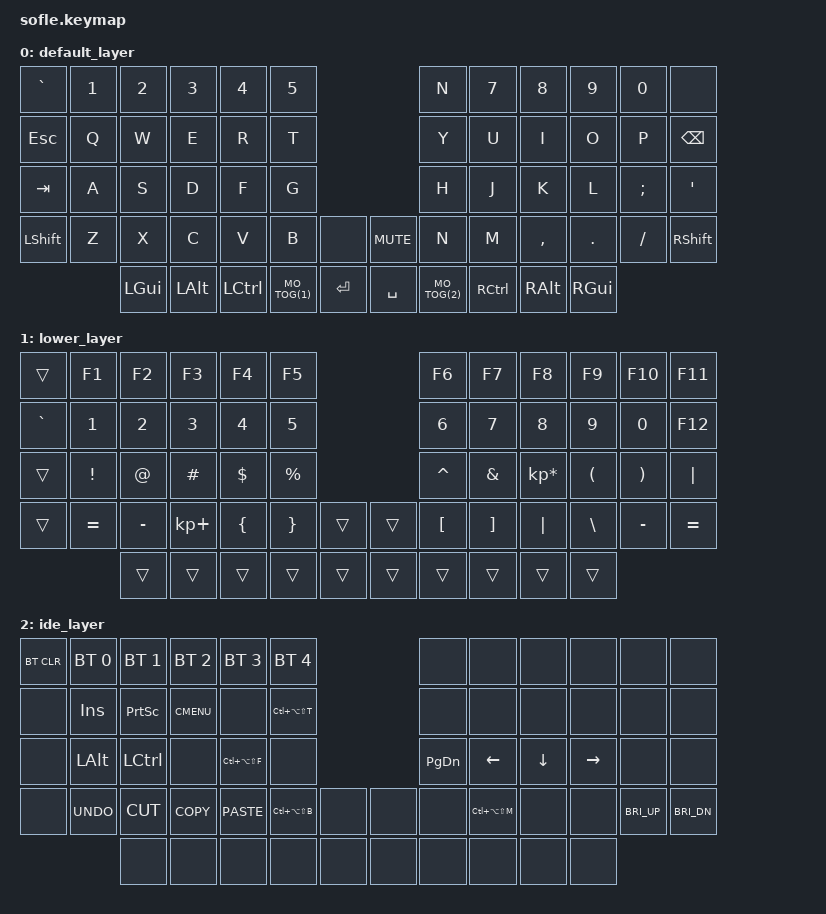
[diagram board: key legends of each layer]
/*
 * Copyright (c) 2020 The ZMK Contributors
 *
 * SPDX-License-Identifier: MIT
 */

#include <behaviors.dtsi>
#include <dt-bindings/zmk/keys.h>
#include <dt-bindings/zmk/bt.h>
#include <dt-bindings/zmk/rgb.h>

#define MO_TOG(layer) &mo_tog layer layer
#define IDE_MENU &kp LC(LA(LS(M)))
#define IDE_TERMFOCUS &kp LC(LA(LS(T)))
#define IDE_FILEFOCUS &kp LC(LA(LS(F)))
#define IDE_SBARFOCUS &kp LC(LA(LS(B)))

/ {
    behaviors {
        mo_tog: behavior_mo_tog {
            compatible = "zmk,behavior-hold-tap";
            #binding-cells = <2>;
            flavor = "hold-preferred";
            tapping-term-ms = <200>;
            bindings = <&mo>, <&tog>;
        };
    };

    keymap {
        compatible = "zmk,keymap";

        default_layer {
// ------------------------------------------------------------------------------------------------------------
// |  `    |  1  |  2  |  3   |  4   |  5   |                   |  6   |  7    |  8    |  9   |   0   |       |
// |  ESC  |  Q  |  W  |  E   |  R   |  T   |                   |  Y   |  U    |  I    |  O   |   P   | BKSPC |
// |  TAB  |  A  |  S  |  D   |  F   |  G   |                   |  H   |  J    |  K    |  L   |   ;   |   '   |
// | SHIFT |  Z  |  X  |  C   |  V   |  B   |        |  |  MUTE |  N   |  M    |  ,    |  .   |   /   | SHIFT |
//               |LGUI | ALT  | CTRL | LOWER|  ENTER |  | SPACE | RAISE| CTRL  | ALT   | GUI  |
            bindings = <
&kp GRAVE &kp N1 &kp N2   &kp N3   &kp N4    &kp N5                             &kp N      &kp N7    &kp N8    &kp N9   &kp N0   &none
&kp ESC   &kp Q  &kp W    &kp E    &kp R     &kp T                              &kp Y      &kp U     &kp I     &kp O    &kp P    &kp BSPC
&kp TAB   &kp A  &kp S    &kp D    &kp F     &kp G                              &kp H      &kp J     &kp K     &kp L    &kp SEMI &kp SQT
&kp LSHFT &kp Z  &kp X    &kp C    &kp V     &kp B      &none       &kp K_MUTE  &kp N      &kp M     &kp COMMA &kp DOT  &kp FSLH &kp RSHFT
                 &kp LGUI &kp LALT &kp LCTRL MO_TOG(1)  &kp RET     &kp SPACE   MO_TOG(2)  &kp RCTRL &kp RALT  &kp RGUI
            >;

            sensor-bindings = <&inc_dec_kp C_BRI_UP C_BRI_DN &inc_dec_kp C_VOL_UP C_VOL_DN>;
        };

        lower_layer {
// TODO: Some binds are waiting for shifted keycode support.
// ------------------------------------------------------------------------------------------------------------
// |       |  F1 |  F2 |  F3  |  F4  |  F5  |                   |  F6  |  F7   |  F8   |  F9  |  F10  |  F11  |
// | `     |  1  |  2  |  3   |  4   |  5   |                   |  6   |   7   |  8    |  9   |   0   |  F12  |
// |       |  !  |  @  |  #   |  $   |  %   |                   |  ^   |   &   |  *    |  (   |   )   |   |   |
// |       |  =  |  -  |  +   |  {   |  }   |        |  |       |  [   |   ]   |  |    |  \   |   -   |   +   |
//               |     |      |      |      |        |  |       |      |       |       |      |
            bindings = <
&trans    &kp F1    &kp F2    &kp F3      &kp F4    &kp F5                    &kp F6    &kp F7   &kp F8          &kp F9    &kp F10   &kp F11
&kp GRAVE &kp N1    &kp N2    &kp N3      &kp N4    &kp N5                    &kp N6    &kp N7   &kp N8          &kp N9    &kp N0    &kp F12
&trans    &kp EXCL  &kp AT    &kp HASH    &kp DLLR  &kp PRCNT                 &kp CARET &kp AMPS &kp KP_MULTIPLY &kp LPAR  &kp RPAR  &kp PIPE
&trans    &kp EQUAL &kp MINUS &kp KP_PLUS &kp LBRC  &kp RBRC  &trans   &trans &kp LBKT  &kp RBKT &kp PIPE        &kp BSLH  &kp MINUS &kp EQUAL
                    &trans    &trans      &trans    &trans    &trans   &trans &trans    &trans   &trans          &trans
            >;

            sensor-bindings = <&inc_dec_kp C_BRI_UP C_BRI_DN &inc_dec_kp C_VOL_UP C_VOL_DN>;
        };

        ide_layer {
// ------------------------------------------------------------------------------------------------------------
// |    BTCLR   |     BT0      |     BT1      |      BT2     |      BT3      |      BT4      |                            |              |              |            |           |             |             |
// |            |     INS      |     PSCR     |     GUI      |               | IDE_TERMFOCUS |                            |     PGUP     |              |      ^     |           |             |             |
// |            |     ALT      |     CTRL     |    FOCFLS    | IDE_FILEFOCUS |     CAPS      |                            |     PGDN     |      <-      |      v     |     ->    |             |             |
// |            |     UNDO     |     CUT      |     COPY     |     PASTE     | IDE_SBARFOCUS |            |  |            |              |   IDE_MENU   |            |           |   BRIGHT    |  DIM        |
//                             |              |              |               |               |            |  |            |              |              |            |           |                       
            bindings = <
    &bt BT_CLR  &bt BT_SEL 0    &bt BT_SEL 1   &bt BT_SEL 2   &bt BT_SEL 3    &bt BT_SEL 4                                 &none           &none          &none       &none       &none          &none
    &none       &kp INS         &kp PSCRN      &kp K_CMENU    &none           IDE_TERMFOCUS                                &none           &none          &none       &none       &none          &none
    &none       &kp LALT        &kp LCTRL      &none          IDE_FILEFOCUS   &none                                        &kp PG_DN       &kp LEFT       &kp DOWN    &kp RIGHT   &none          &none
    &none       &kp K_UNDO      &kp K_CUT      &kp K_COPY     &kp K_PASTE     IDE_SBARFOCUS   &none           &none        &none           IDE_MENU       &none       &none       &kp C_BRI_UP   &kp C_BRI_DN
                                &none          &none          &none           &none           &none           &none        &none           &none          &none       &none                               
            >;

            sensor-bindings = <&inc_dec_kp PG_UP PG_DN &inc_dec_kp C_VOL_UP C_VOL_DN>;
        };
    };
};
